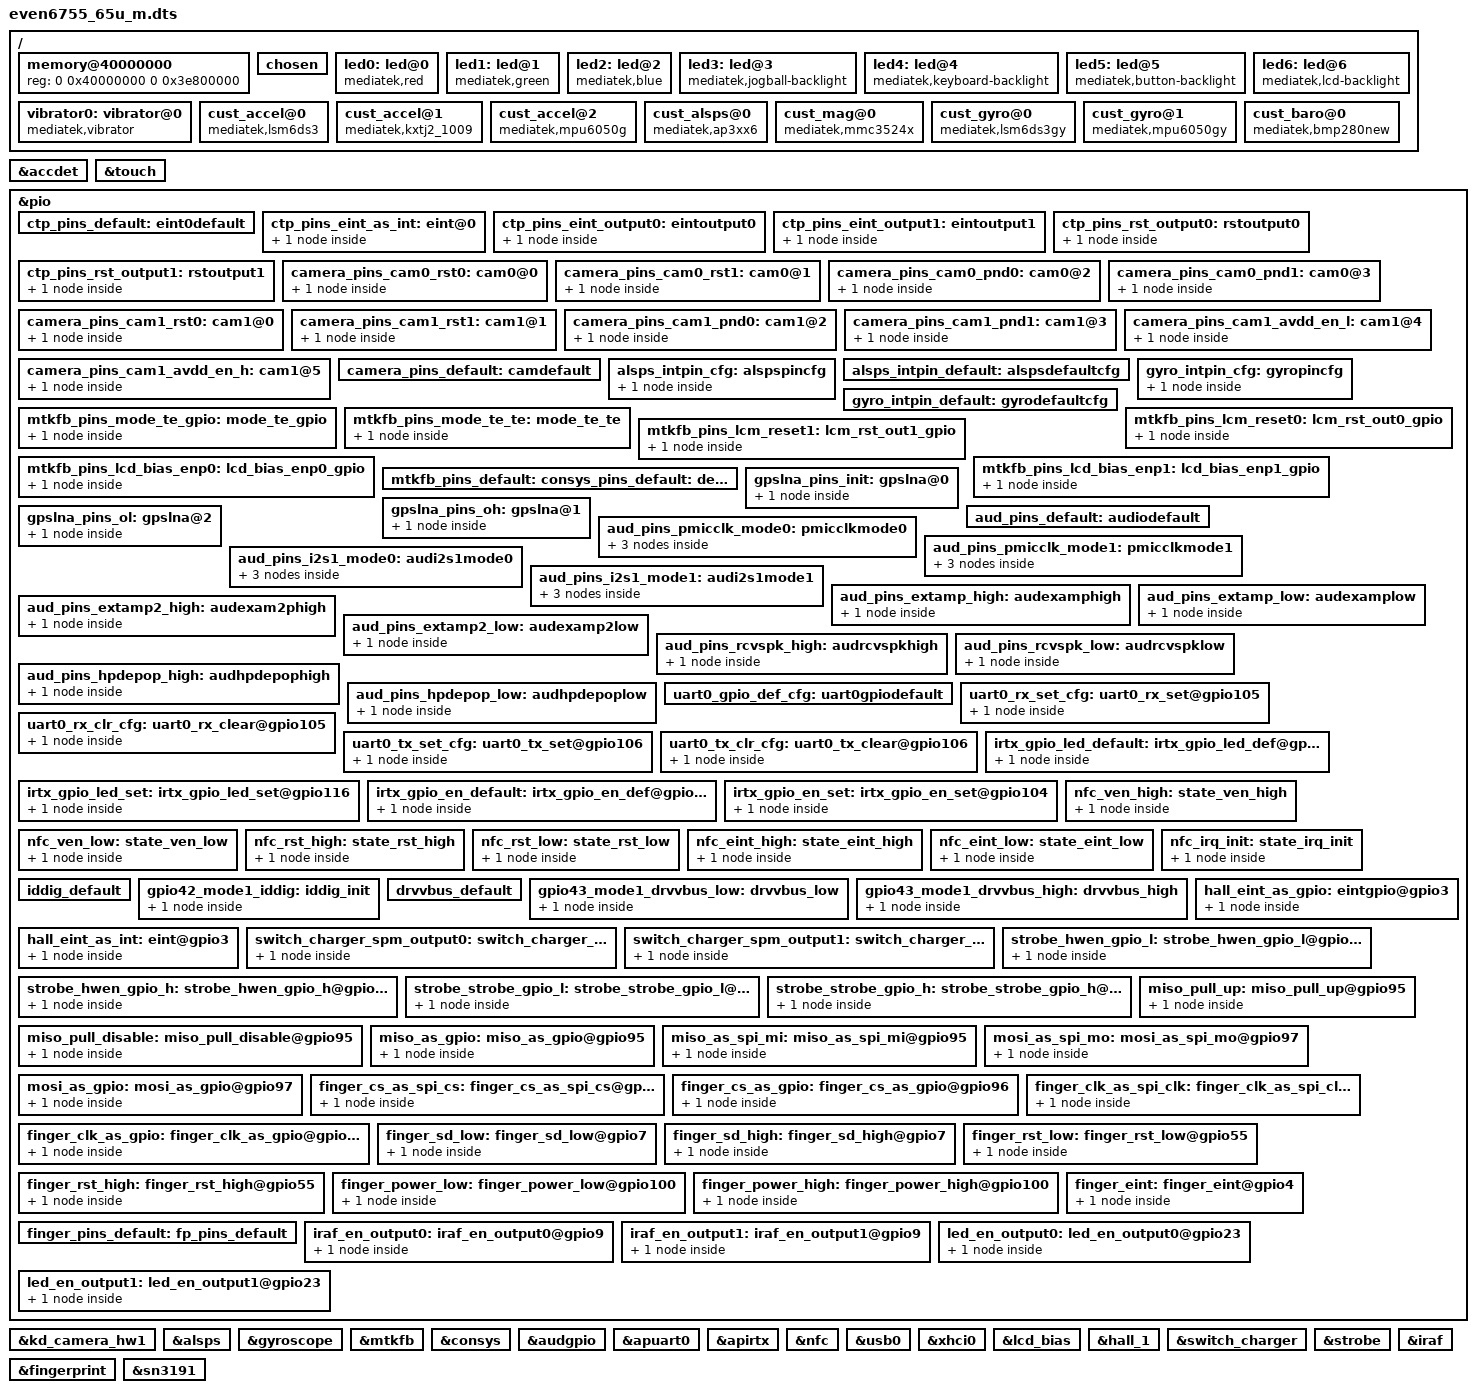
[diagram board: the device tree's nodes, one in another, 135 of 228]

/dts-v1/;

#include "mt6755.dtsi"
#include "cust.dtsi"

/ {
	memory@40000000 {
		device_type = "memory";
		reg = <0 0x40000000 0 0x3e800000>;
	};
	/* chosen */
	chosen {
		bootargs = "console=tty0 console=ttyMT0,921600n1 root=/dev/ram initrd=0x44000000,0x4B434E loglevel=8";

		/* fpga may has no lk, we need to specify display info here */
		/* fb buffer is reserved using this dts by memory node above */
		atag,videolfb-fb_base_h = <0x0>;
		atag,videolfb-fb_base_l = <0x7E800000>;
		atag,videolfb-islcmfound = <1>;
		/* because no lk, so lcm is not inited */
		atag,videolfb-islcm_inited = <0>;
		atag,videolfb-fps= <6000>;
		atag,videolfb-vramSize= <0x01800000>;
		atag,videolfb-lcmname= "nt35695_fhd_dsi_cmd_truly_nt50358_drv";
	};
	led0:led@0 {
		compatible = "mediatek,red";
		led_mode = <2>;
		data = <0>;
		pwm_config = <0 0 0 0 0>;
	};
	led1:led@1 {
		compatible = "mediatek,green";
		led_mode = <2>;
		data = <1>;
		pwm_config = <0 0 0 0 0>;
	};
	led2:led@2 {
		compatible = "mediatek,blue";
		led_mode = <2>;
		data = <2>;
		pwm_config = <0 0 0 0 0>;
	};
	led3:led@3 {
		compatible = "mediatek,jogball-backlight";
		led_mode = <0>;
		data = <1>;
		pwm_config = <0 0 0 0 0>;
	};
	led4:led@4 {
		compatible = "mediatek,keyboard-backlight";
		led_mode = <0>;
		data = <1>;
		pwm_config = <0 0 0 0 0>;
	};
	led5:led@5 {
		compatible = "mediatek,button-backlight";
		led_mode = <3>;
		data = <6>;
		pwm_config = <0 0 0 0 0>;
	};
	led6:led@6 {
		compatible = "mediatek,lcd-backlight";
		led_mode = <5>;
		data = <1>;
		pwm_config = <0 0 0 0 0>;
	};
	vibrator0:vibrator@0 {
		compatible = "mediatek,vibrator";
		vib_timer = <25>;
		vib_limit = <9>;
		vib_vol= <5>;
	};
/*  start sensor */
	cust_accel@0 {
		compatible = "mediatek,lsm6ds3";
		i2c_num	= <1>;
		/* i2c_addr = <0x4c 0 0 0>; */
		direction = <3>;
		power_id = <0xffff>;
		power_vol = <0>;
		firlen = <16>;
		is_batch_supported = <1>;
	};
	cust_accel@1 {
		compatible = "mediatek,kxtj2_1009";
		i2c_num	= <1>;
		/* i2c_addr = <0x4c 0 0 0>; */
		direction = <2>;
		power_id = <0xffff>;
		power_vol = <0>;
		firlen = <6>;
		is_batch_supported = <1>;
	};

	cust_accel@2 {
		compatible = "mediatek,mpu6050g";
		i2c_num	= <1>;
		/* i2c_addr = <0x4c 0 0 0>; */
		direction = <2>;
		power_id = <0xffff>;
		power_vol = <0>;
		firlen = <6>;
		is_batch_supported = <1>;
	};

	cust_alsps@0 {
		compatible		= "mediatek,ap3xx6";
		i2c_num			= <1>;
		i2c_addr		= <0x1e 0 0 0>;
		polling_mode_ps		= <1>;
		polling_mode_als	= <1>;
		power_id		= <0xffff>;
		power_vol		= <0>;
/* Total has 15 level*/
		als_level	= <50 140 637 1027 2297 5588 6730 11301 20449 25768 31122 45552 57937 57937 57937>;
/*  Total has 16 range*/
		als_value	= <0 132 304 502 1004 2003 3006 5006 8004 10000 12000 16000 20000 20000 20000 20000>;
		ps_threshold_high	=  <100>;
		ps_threshold_low	=  <40>;
		is_batch_supported_ps	= <1>;
		is_batch_supported_als	= <1>;
	};

	cust_mag@0 {
		compatible			= "mediatek,mmc3524x";
		i2c_num				= <1>;
		/* i2c_addr			= <0x0d 0 0 0>; */
		direction			= <0>;
		power_id			= <0xffff>;
		power_vol			= <0>;
		/* is_batch_supported		= <0>; */
	};

	cust_gyro@0 {
		compatible			= "mediatek,lsm6ds3gy";
		i2c_num				= <1>;
		/* i2c_addr			= <0x68 0 0 0>; */
		direction			= <3>;
		power_id			= <0xffff>;
		power_vol			= <0>;
		firlen				= <0>;
		is_batch_supported		= <0>;
	};

	cust_gyro@1 {
		compatible			= "mediatek,mpu6050gy";
		i2c_num				= <1>;
		/* i2c_addr			= <0x68 0 0 0>; */
		direction			= <2>;
		power_id			= <0xffff>;
		power_vol			= <0>;
		firlen				= <0>;
		is_batch_supported		= <0>;
	};

	cust_baro@0 {
		compatible			= "mediatek,bmp280new";
		i2c_num				= <1>;
		/* i2c_addr			= <0x68 0 0 0>; */
		direction			= <0>;
		power_id			= <0xffff>;
		power_vol			= <0>;
		firlen				= <32>;
		is_batch_supported		= <0>;
	};
/* end sensor */
};
&accdet {
		accdet-mic-vol = <7>;
		headset-mode-setting = <0x500 0x500 1 0x3F0 0x800 0x800 0x200>;
		accdet-plugout-debounce = <20>;
		/*1:ACC mode, 2:low cost without in bias, 6:low cost with in bias*/
		accdet-mic-mode = <2>;
		/*0--MD_MAX--UP_MAX--DW_MAX*/
		headset-three-key-threshold = <0 80 220 500>;
		/*0--MD_MAX--VOICE_MAX--UP_MAX--DW_MAX*/
		headset-four-key-threshold = <0 58 121 192 450>;
};

/* TOUCH start */
&touch {
	tpd-resolution = <1080 1920>;
	use-tpd-button = <1>;
	tpd-key-num = <3>;
	tpd-key-local= <139 102 158 0>;
	tpd-key-dim-local = <60 2040 100 40 300 2040 100 40 180 2040 100 40 0 0 0 0>;
	tpd-max-touch-num = <5>;
	tpd-filter-enable = <1>;
	tpd-filter-pixel-density = <146>;
	tpd-filter-custom-prameters = <0 0 0 0 0 0 0 0 0 0 0 0>;
	tpd-filter-custom-speed = <0 0 0>;
	pinctrl-names = "default", "state_eint_as_int", "state_eint_output0", "state_eint_output1",
		"state_rst_output0", "state_rst_output1";
	pinctrl-0 = <&ctp_pins_default>;
	pinctrl-1 = <&ctp_pins_eint_as_int>;
	pinctrl-2 = <&ctp_pins_eint_output0>;
	pinctrl-3 = <&ctp_pins_eint_output1>;
	pinctrl-4 = <&ctp_pins_rst_output0>;
	pinctrl-5 = <&ctp_pins_rst_output1>;
	status = "okay";
};
&pio {
	ctp_pins_default: eint0default {
	};
	ctp_pins_eint_as_int: eint@0 {
		pins_cmd_dat {
			pins = <PINMUX_GPIO1__FUNC_GPIO1>;
			slew-rate = <0>;
			bias-disable;
		};
	};
	ctp_pins_eint_output0: eintoutput0 {
		pins_cmd_dat {
			pins = <PINMUX_GPIO1__FUNC_GPIO1>;
			slew-rate = <1>;
			output-low;
		};
	};
	ctp_pins_eint_output1: eintoutput1 {
		pins_cmd_dat {
			pins = <PINMUX_GPIO1__FUNC_GPIO1>;
			slew-rate = <1>;
			output-high;
		};
	};
	ctp_pins_rst_output0: rstoutput0 {
		pins_cmd_dat {
			pins = <PINMUX_GPIO10__FUNC_GPIO10>;
			slew-rate = <1>;
			output-low;
		};
	};
	ctp_pins_rst_output1: rstoutput1 {
		pins_cmd_dat {
			pins = <PINMUX_GPIO10__FUNC_GPIO10>;
			slew-rate = <1>;
			output-high;
		};
	};
};
/* TOUCH end */

/* CAMERA GPIO standardization */
&pio {
	camera_pins_cam0_rst0: cam0@0 {
	    pins_cmd_dat {
			pins = <PINMUX_GPIO110__FUNC_GPIO110>;
			slew-rate = <1>; /*direction 0:in, 1:out*/
			output-low;/*direction out used only. output_low or high*/
		};
	};
	camera_pins_cam0_rst1: cam0@1 {
	    pins_cmd_dat {
			pins = <PINMUX_GPIO110__FUNC_GPIO110>;
			slew-rate = <1>;
			output-high;
		};
	};
	camera_pins_cam0_pnd0: cam0@2 {
	    pins_cmd_dat {
			pins = <PINMUX_GPIO107__FUNC_GPIO107>;
			slew-rate = <1>;
			output-low;
		};
	};
	camera_pins_cam0_pnd1: cam0@3 {
	    pins_cmd_dat {
			pins = <PINMUX_GPIO107__FUNC_GPIO107>;
			slew-rate = <1>;
			output-high;
		};
	};
	camera_pins_cam1_rst0: cam1@0 {
	    pins_cmd_dat {
			pins = <PINMUX_GPIO111__FUNC_GPIO111>;
			slew-rate = <1>; /*direction 0:in, 1:out*/
			output-low;/*direction out used only. output_low or high*/
		};
	};
	camera_pins_cam1_rst1: cam1@1 {
	    pins_cmd_dat {
			pins = <PINMUX_GPIO111__FUNC_GPIO111>;
			slew-rate = <1>;
			output-high;
		};
	};
	camera_pins_cam1_pnd0: cam1@2 {
	    pins_cmd_dat {
			pins = <PINMUX_GPIO108__FUNC_GPIO108>;
			slew-rate = <1>;
			output-low;
		};
	};
	camera_pins_cam1_pnd1: cam1@3 {
	    pins_cmd_dat {
			pins = <PINMUX_GPIO108__FUNC_GPIO108>;
			slew-rate = <1>;
			output-high;
		};
	};

	camera_pins_cam1_avdd_en_l: cam1@4 {
	    pins_cmd_dat {
			pins = <PINMUX_GPIO116__FUNC_GPIO116>;
			slew-rate = <1>;
			output-low;
		};
	};
	camera_pins_cam1_avdd_en_h: cam1@5 {
	    pins_cmd_dat {
			pins = <PINMUX_GPIO116__FUNC_GPIO116>;
			slew-rate = <1>;
			output-high;
		};
	};
	/*camera_pins_cam_ldo_vcama_0: cam@vcama0 {
	};
	camera_pins_cam_ldo_vcama_1: cam@vcama1 {
	};*/
	camera_pins_default: camdefault {
	};

};

&kd_camera_hw1 {
	pinctrl-names = "default",
			"cam0_rst0", "cam0_rst1", "cam0_pnd0", "cam0_pnd1",
			"cam1_rst0", "cam1_rst1", "cam1_pnd0", "cam1_pnd1","cam1_avdd_en_l","cam1_avdd_en_h";
			/*"cam2_rst0", "cam2_rst1", "cam2_pnd0", "cam2_pnd1",
			"cam_ldo_vcama_0", "cam_ldo_vcama_1";*/
	pinctrl-0 = <&camera_pins_default>;
	pinctrl-1 = <&camera_pins_cam0_rst0>;
	pinctrl-2 = <&camera_pins_cam0_rst1>;
	pinctrl-3 = <&camera_pins_cam0_pnd0>;
	pinctrl-4 = <&camera_pins_cam0_pnd1>;
	pinctrl-5 = <&camera_pins_cam1_rst0>;
	pinctrl-6 = <&camera_pins_cam1_rst1>;
	pinctrl-7 = <&camera_pins_cam1_pnd0>;
	pinctrl-8 = <&camera_pins_cam1_pnd1>;
	pinctrl-9 = <&camera_pins_cam1_avdd_en_l>;
	pinctrl-10 = <&camera_pins_cam1_avdd_en_h>;
	/* for main2 */
	/*pinctrl-9 = <&camera_pins_cam2_rst0>;
	pinctrl-10 = <&camera_pins_cam2_rst1>;
	pinctrl-11 = <&camera_pins_cam2_pnd0>;
	pinctrl-12 = <&camera_pins_cam2_pnd1>;*/
	/* for ldo control by gpio */
	/*pinctrl-13 = <&camera_pins_cam_ldo_vcama_0>;
	pinctrl-14 = <&camera_pins_cam_ldo_vcama_1>;*/
	status = "okay";

};
/* CAMERA GPIO end */

&pio {
	alsps_intpin_cfg: alspspincfg {

		pins_cmd_dat {
			pins = <PINMUX_GPIO6__FUNC_GPIO6>;
			slew-rate = <0>;
			bias-pull-up = <00>;
		};
	};

	alsps_intpin_default: alspsdefaultcfg {

	};

	gyro_intpin_cfg: gyropincfg {

		pins_cmd_dat {
			pins = <PINMUX_GPIO4__FUNC_GPIO4>;
			slew-rate = <0>;
			bias-pull-down = <00>;
		};
	};

	gyro_intpin_default: gyrodefaultcfg {

	};
};

&alsps {
	pinctrl-names = "pin_default", "pin_cfg";
	pinctrl-0 = <&alsps_intpin_default>;
	pinctrl-1 = <&alsps_intpin_cfg>;
	status = "okay";
};

&gyroscope {
	pinctrl-names = "pin_default", "pin_cfg";
	pinctrl-0 = <&gyro_intpin_default>;
	pinctrl-1 = <&gyro_intpin_cfg>;
	status = "okay";
};

/* DISPSYS GPIO standardization */
&pio {

	mtkfb_pins_mode_te_gpio: mode_te_gpio {
		pins_cmd_dat {
			pins = <PINMUX_GPIO44__FUNC_GPIO44>;
		};
	};

	mtkfb_pins_mode_te_te: mode_te_te {
		pins_cmd_dat {
			pins = <PINMUX_GPIO44__FUNC_DSI_TE>;
		};
	};

	mtkfb_pins_lcm_reset0: lcm_rst_out0_gpio {
		pins_cmd_dat {
			pins = <PINMUX_GPIO158__FUNC_LCM_RST>;
			slew-rate = <1>;
			output-low;
		};
	};

	mtkfb_pins_lcm_reset1: lcm_rst_out1_gpio {
		pins_cmd_dat {
			pins = <PINMUX_GPIO158__FUNC_LCM_RST>;
			slew-rate = <1>;
			output-high;
		};
	};

	mtkfb_pins_lcd_bias_enp0: lcd_bias_enp0_gpio {
		pins_cmd_dat {
			pins = <PINMUX_GPIO11__FUNC_GPIO11>;
			slew-rate = <1>;
			output-low;
		};
	};

	mtkfb_pins_lcd_bias_enp1: lcd_bias_enp1_gpio {
		pins_cmd_dat {
			pins = <PINMUX_GPIO11__FUNC_GPIO11>;
			slew-rate = <1>;
			output-high;
		};
	};

	mtkfb_pins_default: default {
	};
};

&mtkfb {
	pinctrl-names = "default", "mode_te_gpio", "mode_te_te", "lcm_rst_out0_gpio",
	"lcm_rst_out1_gpio", "lcd_bias_enp0_gpio", "lcd_bias_enp1_gpio";
	pinctrl-0 = <&mtkfb_pins_default>;
	pinctrl-1 = <&mtkfb_pins_mode_te_gpio>;
	pinctrl-2 = <&mtkfb_pins_mode_te_te>;
	pinctrl-3 = <&mtkfb_pins_lcm_reset0>;
	pinctrl-4 = <&mtkfb_pins_lcm_reset1>;
	pinctrl-5 = <&mtkfb_pins_lcd_bias_enp0>;
	pinctrl-6 = <&mtkfb_pins_lcd_bias_enp1>;
	status = "okay";
};/* DISPSYS GPIO standardization end */

/* CONSYS GPIO standardization */
&pio {
	consys_pins_default: default {
	};

	gpslna_pins_init: gpslna@0 {
		pins_cmd_dat {
			pins = <PINMUX_GPIO114__FUNC_GPIO114>;
			slew-rate = <0>;
			bias-disable;
			output-low;
		};
	};

	gpslna_pins_oh: gpslna@1 {
		pins_cmd_dat {
			pins = <PINMUX_GPIO114__FUNC_GPIO114>;
			slew-rate = <1>;
			output-high;
		};
	};

	gpslna_pins_ol: gpslna@2 {
		pins_cmd_dat {
			pins = <PINMUX_GPIO114__FUNC_GPIO114>;
			slew-rate = <1>;
			output-low;
		};
	};
};

&consys {
	pinctrl-names = "default", "gps_lna_state_init", "gps_lna_state_oh", "gps_lna_state_ol";
	pinctrl-0 = <&consys_pins_default>;
	pinctrl-1 = <&gpslna_pins_init>;
	pinctrl-2 = <&gpslna_pins_oh>;
	pinctrl-3 = <&gpslna_pins_ol>;
	status = "okay";
};
/* CONSYS end */

/* AUDIO GPIO standardization */
&audgpio {
	pinctrl-names = "default", "audpmicclk-mode0", "audpmicclk-mode1",
		"audi2s1-mode0", "audi2s1-mode1", "extamp-pullhigh", "extamp-pulllow",
		"extamp2-pullhigh", "extamp2-pulllow", "rcvspk-pullhigh",
		"rcvspk-pulllow","hpdepop-pullhigh","hpdepop-pulllow";
	pinctrl-0 = <&aud_pins_default>;
	pinctrl-1 = <&aud_pins_pmicclk_mode0>;
	pinctrl-2 = <&aud_pins_pmicclk_mode1>;
	pinctrl-3 = <&aud_pins_i2s1_mode0>;
	pinctrl-4 = <&aud_pins_i2s1_mode1>;
	pinctrl-5 = <&aud_pins_extamp_high>;
	pinctrl-6 = <&aud_pins_extamp_low>;
	pinctrl-7 = <&aud_pins_extamp2_high>;
	pinctrl-8 = <&aud_pins_extamp2_low>;
	pinctrl-9 = <&aud_pins_rcvspk_high>;
	pinctrl-10 = <&aud_pins_rcvspk_low>;
	pinctrl-11 = <&aud_pins_hpdepop_high>;
	pinctrl-12 = <&aud_pins_hpdepop_low>;
	status = "okay";
};

&pio {
	aud_pins_default: audiodefault {
	};

	aud_pins_pmicclk_mode0: pmicclkmode0 {
		pins_cmd0_dat {
			pins = <PINMUX_GPIO149__FUNC_GPIO149>;
		};
		pins_cmd1_dat {
			pins = <PINMUX_GPIO150__FUNC_GPIO150>;
			slew-rate = <0>;
			bias-pull-up = <00>;
		};
		pins_cmd2_dat {
			pins = <PINMUX_GPIO151__FUNC_GPIO151>;
		};
	};

	aud_pins_pmicclk_mode1: pmicclkmode1 {
		pins_cmd0_dat {
			pins = <PINMUX_GPIO149__FUNC_AUD_CLK_MOSI>;
		};
		pins_cmd1_dat {
			pins = <PINMUX_GPIO150__FUNC_AUD_DAT_MOSI>;
		};
		pins_cmd2_dat {
			pins = <PINMUX_GPIO151__FUNC_AUD_DAT_MISO>;
		};
	};

	aud_pins_i2s1_mode0: audi2s1mode0 {
		pins_cmd0_dat {
			pins = <PINMUX_GPIO7__FUNC_GPIO7>;
		};
		pins_cmd1_dat {
			pins = <PINMUX_GPIO6__FUNC_GPIO6>;
		};
		pins_cmd2_dat {
			pins = <PINMUX_GPIO5__FUNC_GPIO5>;
		};
	};

	aud_pins_i2s1_mode1: audi2s1mode1 {
		pins_cmd0_dat {
			pins = <PINMUX_GPIO7__FUNC_I2S0_DI>;
		};
		pins_cmd1_dat {
			pins = <PINMUX_GPIO6__FUNC_I2S0_LRCK>;
		};
		pins_cmd2_dat {
			pins = <PINMUX_GPIO5__FUNC_I2S0_BCK>;
		};
	};

	aud_pins_extamp_high: audexamphigh {
		pins_cmd_dat {
			pins = <PINMUX_GPIO115__FUNC_GPIO115>;
			slew-rate = <1>;
			output-high;
		};
	};

	aud_pins_extamp_low: audexamplow {
		pins_cmd_dat {
			pins = <PINMUX_GPIO115__FUNC_GPIO115>;
			slew-rate = <1>;
			output-low;
		};
	};

	aud_pins_extamp2_high: audexam2phigh {
		pins_cmd_dat {
			pins = <PINMUX_GPIO54__FUNC_GPIO54>;
			slew-rate = <1>;
			output-high;
		};
	};
	aud_pins_extamp2_low: audexamp2low {
		pins_cmd_dat {
			pins = <PINMUX_GPIO54__FUNC_GPIO54>;
			slew-rate = <1>;
			output-low;
		};
	};

	aud_pins_rcvspk_high: audrcvspkhigh {
		pins_cmd_dat {
			pins = <PINMUX_GPIO120__FUNC_GPIO120>;
			slew-rate = <1>;
			output-high;
		};
	};

	aud_pins_rcvspk_low: audrcvspklow {
		pins_cmd_dat {
			pins = <PINMUX_GPIO120__FUNC_GPIO120>;
			slew-rate = <1>;
			output-low;
		};
	};

	aud_pins_hpdepop_high: audhpdepophigh {
		pins_cmd_dat {
			pins = <PINMUX_GPIO24__FUNC_GPIO24>;
			slew-rate = <1>;
			output-high;
		};
	};

	aud_pins_hpdepop_low: audhpdepoplow {
		pins_cmd_dat {
			pins = <PINMUX_GPIO24__FUNC_GPIO24>;
			slew-rate = <1>;
			output-low;
		};
	};
};
/* AUDIO GPIO end */

/* UART GPIO */
&apuart0 {
	pinctrl-names = "uart0_gpio_default",
			"uart0_rx_set",
			"uart0_rx_clear",
			"uart0_tx_set",
			"uart0_tx_clear";
	pinctrl-0 = <&uart0_gpio_def_cfg>;
	pinctrl-1 = <&uart0_rx_set_cfg>;
	pinctrl-2 = <&uart0_rx_clr_cfg>;
	pinctrl-3 = <&uart0_tx_set_cfg>;
	pinctrl-4 = <&uart0_tx_clr_cfg>;
	status = "okay";
};

&pio {
	/* UART GPIO Settings - Start */
	/* UART0: rx set, rx clear, tx clear, tx clear*/
	uart0_gpio_def_cfg:uart0gpiodefault {

	};
	uart0_rx_set_cfg:uart0_rx_set@gpio105 {
		pins_cmd_dat {
			pins = <PINMUX_GPIO105__FUNC_URXD0>;
		};
	};
	uart0_rx_clr_cfg:uart0_rx_clear@gpio105  {
		pins_cmd_dat {
			pins = <PINMUX_GPIO105__FUNC_GPIO105>;
			slew-rate = <1>;
			output-high;
		};
	};
	uart0_tx_set_cfg:uart0_tx_set@gpio106  {
		pins_cmd_dat {
			pins = <PINMUX_GPIO106__FUNC_UTXD0>;
		};
	};
	uart0_tx_clr_cfg:uart0_tx_clear@gpio106  {
		pins_cmd_dat {
			pins = <PINMUX_GPIO106__FUNC_GPIO106>;
			slew-rate = <1>;
			output-high;
		};
	};
};/* UART GPIO end */

/* IRTX GPIO end */
&apirtx {
	pinctrl-names = "irtx_gpio_led_default",
			"irtx_gpio_led_set",
			"irtx_gpio_en_default",
			"irtx_gpio_en_set";

	pinctrl-0 = <&irtx_gpio_led_default>;
	pinctrl-1 = <&irtx_gpio_led_set>;
	pinctrl-2 = <&irtx_gpio_en_default>;
	pinctrl-3 = <&irtx_gpio_en_set>;
	status = "okay";
};
&pio {
	/* IRTX GPIO Settings -Start */
	/* default: GPIO0, output, high */
	irtx_gpio_led_default:irtx_gpio_led_def@gpio116 {
		pins_cmd_dat {
			pins = <PINMUX_GPIO116__FUNC_GPIO116>;
			slew-rate = <1>;
			bias-disable;
			output-low;
			input-schmitt-enable = <0>;
		};
	};

	irtx_gpio_led_set:irtx_gpio_led_set@gpio116 {
		pins_cmd_dat {
			pins = <PINMUX_GPIO116__FUNC_IRTX_OUT>;
			slew-rate = <1>;
			output-high;
		};
	};

	irtx_gpio_en_default:irtx_gpio_en_def@gpio104 {
		pins_cmd_dat {
			pins = <PINMUX_GPIO104__FUNC_GPIO104>;
			slew-rate = <1>;
			bias-disable;
			output-low;
			input-schmitt-enable = <0>;
		};
	};

	irtx_gpio_en_set:irtx_gpio_en_set@gpio104 {
		pins_cmd_dat {
			pins = <PINMUX_GPIO104__FUNC_GPIO104>;
			slew-rate = <1>;
			output-high;
		};
	};


}; /* IRTX GPIO Settings -End */

/* NFC GPIO standardization */
&pio {
	nfc_default: default {

	};

	nfc_ven_high: state_ven_high {
		pins_cmd_dat {
			pins = <PINMUX_GPIO26__FUNC_GPIO26>;
			slew-rate = <1>;
			output-high;
		};
	};

	nfc_ven_low: state_ven_low {
		pins_cmd_dat {
			pins = <PINMUX_GPIO26__FUNC_GPIO26>;
			slew-rate = <1>;
			output-low;
		};
	};

	nfc_rst_high: state_rst_high {
		pins_cmd_dat {
			pins = <PINMUX_GPIO25__FUNC_GPIO25>;
			slew-rate = <1>;
			output-high;
		};
	};

	nfc_rst_low: state_rst_low {
		pins_cmd_dat {
			pins = <PINMUX_GPIO25__FUNC_GPIO25>;
			slew-rate = <1>;
			output-low;
		};
	};

	nfc_eint_high: state_eint_high {
		pins_cmd_dat {
			pins = <PINMUX_GPIO27__FUNC_GPIO27>;
			slew-rate = <1>;
			output-high;
		};
	};

	nfc_eint_low: state_eint_low {
		pins_cmd_dat {
			pins = <PINMUX_GPIO27__FUNC_GPIO27>;
			slew-rate = <1>;
			output-low;
		};
	};

	nfc_irq_init: state_irq_init {
		pins_cmd_dat {
			pins = <PINMUX_GPIO28__FUNC_GPIO28>;
			slew-rate = <0>;
			bias-pull-down = <00>;
		};
	};
};

&nfc {
	pinctrl-names = "default", "ven_high", "ven_low", "rst_high", "rst_low", "eint_high", "eint_low", "irq_init";
	pinctrl-0 = <&nfc_default>;
	pinctrl-1 = <&nfc_ven_high>;
	pinctrl-2 = <&nfc_ven_low>;
	pinctrl-3 = <&nfc_rst_high>;
	pinctrl-4 = <&nfc_rst_low>;
	pinctrl-5 = <&nfc_eint_high>;
	pinctrl-6 = <&nfc_eint_low>;
	pinctrl-7 = <&nfc_irq_init>;
	status = "okay";
};
/* NFC end */

&pio {
	iddig_default: iddig_default {
	};

	gpio42_mode1_iddig: iddig_init {
		pins_cmd_dat {
			pins = <PINMUX_GPIO42__FUNC_IDDIG>;
			slew-rate = <0>;
			bias-pull-up = <00>;
		};
	};
};

&pio {
	drvvbus_default: drvvbus_default {
	};

	gpio43_mode1_drvvbus_low: drvvbus_low {
		pins_cmd_dat {
			pins = <PINMUX_GPIO43__FUNC_USB_DRVVBUS>;
			slew-rate = <1>;
			output-low;
		};
	};

	gpio43_mode1_drvvbus_high: drvvbus_high {
		pins_cmd_dat {
			pins = <PINMUX_GPIO43__FUNC_USB_DRVVBUS>;
			slew-rate = <1>;
			output-high;
		};
	};
};

&usb0 {
	pinctrl-names = "iddig_default", "iddig_init";
	pinctrl-0 = <&iddig_default>;
	pinctrl-1 = <&gpio42_mode1_iddig>;
	status = "okay";
};

&xhci0 {
	pinctrl-names = "drvvbus_default", "drvvbus_low", "drvvbus_high";
	pinctrl-0 = <&drvvbus_default>;
	pinctrl-1 = <&gpio43_mode1_drvvbus_low>;
	pinctrl-2 = <&gpio43_mode1_drvvbus_high>;
	status = "okay";
};

/* LCM BIAS start*/

&lcd_bias {
	debounce = <4 1>;
   	vop_en_pin = <63>;
	von_en_pin = <64>;
	gpio_test = <86>;
	status = "okay";
};

/* LCM BIAS end*/

/* HALL start */

&hall_1 {
	debounce = <3 1>;
	pinctrl-names = "hall_eint_as_gpio", "hall_eint_as_int";
	pinctrl-0 = <&hall_eint_as_gpio>;
	pinctrl-1 = <&hall_eint_as_int>;
	status = "okay";
};
&pio {

	hall_eint_as_gpio: eintgpio@gpio3 {
		pins_cmd_dat {
			pins = <PINMUX_GPIO3__FUNC_GPIO3>;
			slew-rate = <0>;
			bias-pull-up = <00>;
		};
	};

	hall_eint_as_int: eint@gpio3 {
		pins_cmd_dat {
			pins = <PINMUX_GPIO3__FUNC_GPIO3>;
			slew-rate = <0>;
			bias-pull-up = <00>;
		};
	};
};
/* HALL end */

/* switch_charger start */
&switch_charger {
	pinctrl-names = "switch_charger_spm_output0", "switch_charger_spm_output1";
	pinctrl-0 = <&switch_charger_spm_output0>;
	pinctrl-1 = <&switch_charger_spm_output1>;
	status = "okay";
};

&pio {

	switch_charger_spm_output0: switch_charger_spm_output0@gpio85 {
		pins_cmd_dat {
			pins = <PINMUX_GPIO85__FUNC_GPIO85>;
			slew-rate = <1>;
			bias-disable;
			output-low;
		};
	};

	switch_charger_spm_output1: switch_charger_spm_output1@gpio85 {
		pins_cmd_dat {
			pins = <PINMUX_GPIO85__FUNC_GPIO85>;
			slew-rate = <1>;
			bias-disable;
			output-high;
		};
	};
};
/* switch_charger end */

/* strobe start */
&strobe {
	pinctrl-names = "strobe_hwen_gpio_l", "strobe_hwen_gpio_h", "strobe_strobe_gpio_l", "strobe_strobe_gpio_h";
	pinctrl-0 = <&strobe_hwen_gpio_l>;
	pinctrl-1 = <&strobe_hwen_gpio_h>;
	pinctrl-2 = <&strobe_strobe_gpio_l>;
	pinctrl-3 = <&strobe_strobe_gpio_h>;
	status = "okay";
};

&pio {
	strobe_hwen_gpio_l: strobe_hwen_gpio_l@gpio87 {
		pins_cmd_dat {
			pins = <PINMUX_GPIO87__FUNC_GPIO87>;
			slew-rate = <1>;
			bias-disable;
			output-low;
		};
	};

	strobe_hwen_gpio_h: strobe_hwen_gpio_h@gpio87 {
		pins_cmd_dat {
			pins = <PINMUX_GPIO87__FUNC_GPIO87>;
			slew-rate = <1>;
			bias-disable;
			output-high;
		};
	};

	strobe_strobe_gpio_l: strobe_strobe_gpio_l@gpio45 {
		pins_cmd_dat {
			pins = <PINMUX_GPIO45__FUNC_GPIO45>;
			slew-rate = <1>;
			bias-disable;
			output-low;
		};
	};

	strobe_strobe_gpio_h: strobe_strobe_gpio_h@gpio45 {
		pins_cmd_dat {
			pins = <PINMUX_GPIO45__FUNC_GPIO45>;
			slew-rate = <1>;
			bias-disable;
			output-high;
		};
	};

};
/* strobe end */


/* fingerprint start */
&fingerprint {
	debounce = <4 1>;
	pinctrl-names = "miso_pull_up","miso_pull_disable","miso_as_gpio","miso_as_spi_mi","mosi_as_spi_mo","mosi_as_gpio",
					"finger_sd_low","finger_sd_high","finger_cs_as_spi_cs","finger_cs_as_gpio","finger_rst_low","finger_rst_high",
					"finger_power_low","finger_power_high","finger_eint","finger_clk_as_spi_clk","finger_clk_as_gpio","default";
	pinctrl-0 = <&miso_pull_up>;
	pinctrl-1 = <&miso_pull_disable>;
	pinctrl-2 = <&miso_as_gpio>;
	pinctrl-3 = <&miso_as_spi_mi>;	
	pinctrl-4 = <&mosi_as_spi_mo>;
	pinctrl-5 = <&mosi_as_gpio>;
	pinctrl-6 = <&finger_sd_low>;
	pinctrl-7 = <&finger_sd_high>;
	pinctrl-8 = <&finger_cs_as_spi_cs>;
	pinctrl-9 = <&finger_cs_as_gpio>;	
	pinctrl-10 = <&finger_rst_low>;
	pinctrl-11 = <&finger_rst_high>;
	pinctrl-12 = <&finger_power_low>;
	pinctrl-13 = <&finger_power_high>;
	pinctrl-14 = <&finger_eint>;
	pinctrl-15 = <&finger_clk_as_spi_clk>;
	pinctrl-16 = <&finger_clk_as_gpio>;
	pinctrl-17 = <&finger_pins_default>;
	status = "okay";
};
&pio {

	miso_pull_up: miso_pull_up@gpio95 {
		pins_cmd_dat {
			pins = <PINMUX_GPIO95__FUNC_GPIO95>;
			slew-rate = <0>;
			bias-pull-up = <11>;
			output-low;
		};
	};
	miso_pull_disable: miso_pull_disable@gpio95 {
		pins_cmd_dat {
			pins = <PINMUX_GPIO95__FUNC_GPIO95>;
			slew-rate = <0>;
			bias-disable;
			output-low;
		};
	};
	
	miso_as_gpio: miso_as_gpio@gpio95 {
		pins_cmd_dat {
			pins = <PINMUX_GPIO95__FUNC_GPIO95>;
			slew-rate = <0>;
			bias-disable;
			output-low;
			input-schmitt-enable = <0>;
		};
	};
	miso_as_spi_mi: miso_as_spi_mi@gpio95 {
		pins_cmd_dat {
			pins = <PINMUX_GPIO95__FUNC_SPI0_MI>;
			slew-rate = <0>;
			bias-disable;
			output-low;
			input-schmitt-enable = <0>;
		};
	};
	
	mosi_as_spi_mo: mosi_as_spi_mo@gpio97 {
		pins_cmd_dat {
			pins = <PINMUX_GPIO97__FUNC_SPI0_MO>;
			slew-rate = <0>;
			bias-disable;
			output-low;
			input-schmitt-enable = <0>;
		};
	};
	mosi_as_gpio: mosi_as_gpio@gpio97 {
		pins_cmd_dat {
			pins = <PINMUX_GPIO97__FUNC_GPIO97>;
			slew-rate = <0>;
			bias-disable;
			output-low;
			input-schmitt-enable = <0>;
		};
	};

	
	finger_cs_as_spi_cs: finger_cs_as_spi_cs@gpio96 {
		pins_cmd_dat {
			pins = <PINMUX_GPIO96__FUNC_SPI0_CSB>;
			slew-rate = <1>;
			bias-disable;
			output-low;
			input-schmitt-enable = <0>;
		};
	};
	finger_cs_as_gpio: finger_cs_as_gpio@gpio96 {
		pins_cmd_dat {
			pins = <PINMUX_GPIO96__FUNC_GPIO96>;
			slew-rate = <1>;
			bias-disable;
			output-low;
			input-schmitt-enable = <0>;
		};
	};	
	
	finger_clk_as_spi_clk: finger_clk_as_spi_clk@gpio98 {
		pins_cmd_dat {
			pins = <PINMUX_GPIO98__FUNC_SPI0_CLK>;
			slew-rate = <1>;
			bias-disable;
			output-low;
			input-schmitt-enable = <0>;
		};
	};
		
	finger_clk_as_gpio: finger_clk_as_gpio@gpio98 {
		pins_cmd_dat {
			pins = <PINMUX_GPIO98__FUNC_GPIO98>;
			slew-rate = <1>;
			bias-disable;
			output-low;
			input-schmitt-enable = <0>;
		};
	};
		
	finger_sd_low: finger_sd_low@gpio7 {
		pins_cmd_dat {
			pins = <PINMUX_GPIO7__FUNC_GPIO7>;
			slew-rate = <1>;
			bias-disable;
			output-low;
		};
	};
	finger_sd_high: finger_sd_high@gpio7 {
		pins_cmd_dat {
			pins = <PINMUX_GPIO7__FUNC_GPIO7>;
			slew-rate = <1>;
			bias-disable;
			output-high;
		};
	};
	
	finger_rst_low: finger_rst_low@gpio55 {
		pins_cmd_dat {
			pins = <PINMUX_GPIO55__FUNC_GPIO55>;
			slew-rate = <1>;
			bias-disable;
			output-low;
		};
	};
	finger_rst_high: finger_rst_high@gpio55 {
		pins_cmd_dat {
			pins = <PINMUX_GPIO55__FUNC_GPIO55>;
			slew-rate = <1>;
			bias-disable;
			output-high;
		};
	};
	
	finger_power_low: finger_power_low@gpio100 {
		pins_cmd_dat {
			pins = <PINMUX_GPIO100__FUNC_GPIO100>;
			slew-rate = <1>;
			bias-disable;
			output-low;
		};
	};
		
	finger_power_high: finger_power_high@gpio100 {
		pins_cmd_dat {
			pins = <PINMUX_GPIO100__FUNC_GPIO100>;
			slew-rate = <1>;
			bias-disable;
			output-high;
		};
	};
	
	finger_eint: finger_eint@gpio4{\
		pins_cmd_dat {
			pins = <PINMUX_GPIO4__FUNC_GPIO4>;
			slew-rate = <0>;
			bias-pull-up = <00>;
		};
	};
	
	finger_pins_default:fp_pins_default{
	};
};
/*  fingerprint end*/

/* iraf start */
&iraf {
	pinctrl-names = "iraf_en_output0", "iraf_en_output1";
	pinctrl-0 = <&iraf_en_output0>;
	pinctrl-1 = <&iraf_en_output1>;
	status = "okay";
};
&pio {

	iraf_en_output0: iraf_en_output0@gpio9 {
		pins_cmd_dat {
			pins = <PINMUX_GPIO9__FUNC_GPIO9>;
			slew-rate = <1>;
			bias-disable;
			output-low;
		};
	};

	iraf_en_output1: iraf_en_output1@gpio9 {
		pins_cmd_dat {
			pins = <PINMUX_GPIO9__FUNC_GPIO9>;
			slew-rate = <1>;
			bias-disable;
			output-high;
		};
	};
};
/* iraf end */


/* led start */

&sn3191 {
	pinctrl-names = "led_en_output0", "led_en_output1";
	pinctrl-0 = <&led_en_output0>;
	pinctrl-1 = <&led_en_output1>;
	status = "okay";
};
&pio {

	led_en_output0: led_en_output0@gpio23 {
		pins_cmd_dat {
			pins = <PINMUX_GPIO23__FUNC_GPIO23>;
			slew-rate = <1>;
			bias-disable;
			output-low;
		};
	};

	led_en_output1: led_en_output1@gpio23 {
		pins_cmd_dat {
			pins = <PINMUX_GPIO23__FUNC_GPIO23>;
			slew-rate = <1>;
			bias-disable;
			output-high;
		};
	};
};
/* led end */


